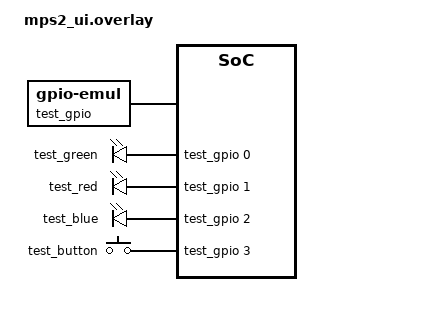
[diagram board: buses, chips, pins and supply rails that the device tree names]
#include <zephyr/dt-bindings/gpio/gpio.h>
#include <zephyr/dt-bindings/input/input-event-codes.h>

/ {
    test_gpio: gpio-emulator {
        compatible = "zephyr,gpio-emul";
        gpio-controller;
        #gpio-cells = <2>;
        ngpios = <4>;
        rising-edge;
        falling-edge;
    };

    leds {
        test_green: test_green {
            gpios = <&test_gpio 0 GPIO_ACTIVE_HIGH>;
        };
        test_red: test_red {
            gpios = <&test_gpio 1 GPIO_ACTIVE_HIGH>;
        };
        test_blue: test_blue {
            gpios = <&test_gpio 2 GPIO_ACTIVE_HIGH>;
        };
    };

    gpio_keys {
        test_button: test_button {
            gpios = <&test_gpio 3 GPIO_ACTIVE_HIGH>;
            zephyr,code = <INPUT_KEY_2>;
        };
    };

    aliases {
        led0 = &test_green;
        led1 = &test_red;
        led2 = &test_blue;
        sw0 = &test_button;
    };
};
